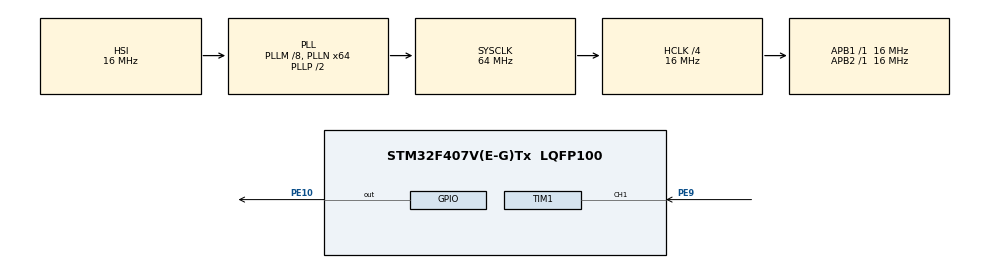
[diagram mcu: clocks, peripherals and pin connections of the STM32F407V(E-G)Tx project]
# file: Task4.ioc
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Mcu.Family=STM32F4
Mcu.Name=STM32F407V(E-G)Tx
Mcu.Package=LQFP100
NVIC.PriorityGroup=NVIC_PRIORITYGROUP_4
NVIC.TIM1_CC_IRQn=true\:0\:0\:false\:false\:true\:true\:true\:true
NVIC.TIM1_UP_TIM10_IRQn=true\:0\:0\:false\:false\:true\:true\:true\:true
PA13.Mode=Serial_Wire
PA13.Signal=SYS_JTMS-SWDIO
PA14.Mode=Serial_Wire
PA14.Signal=SYS_JTCK-SWCLK
PE10.Signal=GPIO_Output
PE9.Signal=S_TIM1_CH1
ProjectManager.HeapSize=0x200
ProjectManager.StackSize=0x400
ProjectManager.TargetToolchain=CMake
RCC.48MHZClocksFreq_Value=32000000
RCC.AHBCLKDivider=RCC_SYSCLK_DIV4
RCC.AHBFreq_Value=16000000
RCC.APB1Freq_Value=16000000
RCC.APB1TimFreq_Value=16000000
RCC.APB2Freq_Value=16000000
RCC.APB2TimFreq_Value=16000000
RCC.CortexFreq_Value=16000000
RCC.HCLKFreq_Value=16000000
RCC.HSE_VALUE=25000000
RCC.HSI_VALUE=16000000
RCC.LSE_VALUE=32768
RCC.PLLM=8
RCC.PLLN=64
RCC.SYSCLKFreq_VALUE=64000000
RCC.SYSCLKSource=RCC_SYSCLKSOURCE_PLLCLK
RCC.VCOOutputFreq_Value=128000000
SH.S_TIM1_CH1.0=TIM1_CH1,Input_Capture1_from_TI1
TIM1.Channel-Input_Capture1_from_TI1=TIM_CHANNEL_1
TIM1.Prescaler=15
VP_TIM1_VS_ClockSourceINT.Mode=Internal
board=custom

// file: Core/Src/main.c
/* USER CODE BEGIN Header */
/**
  ******************************************************************************
  * @file           : main.c
  * @brief          : Main program body
  ******************************************************************************
  * @attention
  *
  * Copyright (c) 2025 STMicroelectronics.
  * All rights reserved.
  *
  * This software is licensed under terms that can be found in the LICENSE file
  * in the root directory of this software component.
  * If no LICENSE file comes with this software, it is provided AS-IS.
  *
  ******************************************************************************
  */
/* USER CODE END Header */
#include "main.h"

TIM_HandleTypeDef htim1;

void SystemClock_Config(void);
static void MX_GPIO_Init(void);
static void MX_TIM1_Init(void);
/* USER CODE BEGIN PFP */
uint8_t flag = 0;
uint8_t tim1_counter = 0;
uint8_t tim2_counter = 0;
uint8_t distance = 0;
uint16_t driff = 0;
/* USER CODE END PFP */

/* USER CODE BEGIN 0 */
void Delay_us(uint8_t time_us) {
  HAL_TIM_Base_Start(&htim1);
  while (htim1.Instance->CNT < time_us) {

  }
  HAL_TIM_Base_Stop(&htim1);
}
void trigger_state(void) {
  HAL_GPIO_WritePin(GPIOE, GPIO_PIN_10, GPIO_PIN_SET);
  Delay_us(10);
  HAL_GPIO_WritePin(GPIOE, GPIO_PIN_10, GPIO_PIN_RESET);
  __HAL_TIM_ENABLE_IT(&htim1, TIM_IT_CC1);
}
void HAL_TIM_IC_CaptureCallback(TIM_HandleTypeDef *htim){
  if (htim->Channel == HAL_TIM_ACTIVE_CHANNEL_1 ) {
    if (flag == 0) {
      tim1_counter =  HAL_TIM_ReadCapturedValue(&htim1, TIM_CHANNEL_1);
      flag = 1;
      __HAL_TIM_SET_CAPTUREPOLARITY(&htim1,TIM_CHANNEL_1,TIM_ICPOLARITY_FALLING);
    }
    else if (flag == 1) {
      tim2_counter =  HAL_TIM_ReadCapturedValue(&htim1, TIM_CHANNEL_1);
      __HAL_TIM_SET_COUNTER(htim,0);
      if (tim1_counter - tim2_counter > 0) {
        driff = tim1_counter - tim2_counter;
      }
      else if (tim1_counter - tim2_counter < 0) {
        driff = 0xffff + tim2_counter - tim1_counter;
      }
      distance = 0.017*driff;
      flag = 0;
      __HAL_TIM_SET_CAPTUREPOLARITY(&htim1,TIM_CHANNEL_1,TIM_INPUTCHANNELPOLARITY_RISING);
      __HAL_TIM_DISABLE_IT(&htim1, TIM_IT_CC1);
    }
  }
}
/* USER CODE END 0 */

int main(void)
{

  /* MCU Configuration--------------------------------------------------------*/

  /* Reset of all peripherals, Initializes the Flash interface and the Systick. */
  HAL_Init();

  /* Configure the system clock */
  SystemClock_Config();

  /* Initialize all configured peripherals */
  MX_GPIO_Init();
  MX_TIM1_Init();
  /* USER CODE BEGIN 2 */
  HAL_TIM_IC_Start_IT(&htim1, TIM_CHANNEL_1);

  /* USER CODE END 2 */

  /* Infinite loop */
  while (1)
  {

    /* USER CODE BEGIN 3 */
    trigger_state();
    HAL_Delay(100);
  }
  /* USER CODE END 3 */
}

void SystemClock_Config(void)
{
  RCC_OscInitTypeDef RCC_OscInitStruct = {0};
  RCC_ClkInitTypeDef RCC_ClkInitStruct = {0};

  /** Configure the main internal regulator output voltage
  */
  __HAL_RCC_PWR_CLK_ENABLE();
  __HAL_PWR_VOLTAGESCALING_CONFIG(PWR_REGULATOR_VOLTAGE_SCALE1);

  /** Initializes the RCC Oscillators according to the specified parameters
  * in the RCC_OscInitTypeDef structure.
  */
  RCC_OscInitStruct.OscillatorType = RCC_OSCILLATORTYPE_HSI;
  RCC_OscInitStruct.HSIState = RCC_HSI_ON;
  RCC_OscInitStruct.HSICalibrationValue = RCC_HSICALIBRATION_DEFAULT;
  RCC_OscInitStruct.PLL.PLLState = RCC_PLL_ON;
  RCC_OscInitStruct.PLL.PLLSource = RCC_PLLSOURCE_HSI;
  RCC_OscInitStruct.PLL.PLLM = 8;
  RCC_OscInitStruct.PLL.PLLN = 64;
  RCC_OscInitStruct.PLL.PLLP = RCC_PLLP_DIV2;
  RCC_OscInitStruct.PLL.PLLQ = 4;
  if (HAL_RCC_OscConfig(&RCC_OscInitStruct) != HAL_OK)
  {
    Error_Handler();
  }

  /** Initializes the CPU, AHB and APB buses clocks
  */
  RCC_ClkInitStruct.ClockType = RCC_CLOCKTYPE_HCLK|RCC_CLOCKTYPE_SYSCLK
                              |RCC_CLOCKTYPE_PCLK1|RCC_CLOCKTYPE_PCLK2;
  RCC_ClkInitStruct.SYSCLKSource = RCC_SYSCLKSOURCE_PLLCLK;
  RCC_ClkInitStruct.AHBCLKDivider = RCC_SYSCLK_DIV4;
  RCC_ClkInitStruct.APB1CLKDivider = RCC_HCLK_DIV1;
  RCC_ClkInitStruct.APB2CLKDivider = RCC_HCLK_DIV1;

  if (HAL_RCC_ClockConfig(&RCC_ClkInitStruct, FLASH_LATENCY_0) != HAL_OK)
  {
    Error_Handler();
  }
}

static void MX_TIM1_Init(void)
{

  TIM_ClockConfigTypeDef sClockSourceConfig = {0};
  TIM_MasterConfigTypeDef sMasterConfig = {0};
  TIM_IC_InitTypeDef sConfigIC = {0};

  htim1.Instance = TIM1;
  htim1.Init.Prescaler = 15;
  htim1.Init.CounterMode = TIM_COUNTERMODE_UP;
  htim1.Init.Period = 65535;
  htim1.Init.ClockDivision = TIM_CLOCKDIVISION_DIV1;
  htim1.Init.RepetitionCounter = 0;
  htim1.Init.AutoReloadPreload = TIM_AUTORELOAD_PRELOAD_DISABLE;
  if (HAL_TIM_Base_Init(&htim1) != HAL_OK)
  {
    Error_Handler();
  }
  sClockSourceConfig.ClockSource = TIM_CLOCKSOURCE_INTERNAL;
  if (HAL_TIM_ConfigClockSource(&htim1, &sClockSourceConfig) != HAL_OK)
  {
    Error_Handler();
  }
  if (HAL_TIM_IC_Init(&htim1) != HAL_OK)
  {
    Error_Handler();
  }
  sMasterConfig.MasterOutputTrigger = TIM_TRGO_RESET;
  sMasterConfig.MasterSlaveMode = TIM_MASTERSLAVEMODE_DISABLE;
  if (HAL_TIMEx_MasterConfigSynchronization(&htim1, &sMasterConfig) != HAL_OK)
  {
    Error_Handler();
  }
  sConfigIC.ICPolarity = TIM_INPUTCHANNELPOLARITY_RISING;
  sConfigIC.ICSelection = TIM_ICSELECTION_DIRECTTI;
  sConfigIC.ICPrescaler = TIM_ICPSC_DIV1;
  sConfigIC.ICFilter = 0;
  if (HAL_TIM_IC_ConfigChannel(&htim1, &sConfigIC, TIM_CHANNEL_1) != HAL_OK)
  {
    Error_Handler();
  }

}

static void MX_GPIO_Init(void)
{
  GPIO_InitTypeDef GPIO_InitStruct = {0};

  /* GPIO Ports Clock Enable */
  __HAL_RCC_GPIOE_CLK_ENABLE();
  __HAL_RCC_GPIOA_CLK_ENABLE();

  /*Configure GPIO pin Output Level */
  HAL_GPIO_WritePin(GPIOE, GPIO_PIN_10, GPIO_PIN_RESET);

  /*Configure GPIO pin : PE10 */
  GPIO_InitStruct.Pin = GPIO_PIN_10;
  GPIO_InitStruct.Mode = GPIO_MODE_OUTPUT_PP;
  GPIO_InitStruct.Pull = GPIO_NOPULL;
  GPIO_InitStruct.Speed = GPIO_SPEED_FREQ_LOW;
  HAL_GPIO_Init(GPIOE, &GPIO_InitStruct);

}

void Error_Handler(void)
{
  __disable_irq();
  while (1)
  {
  }
}
